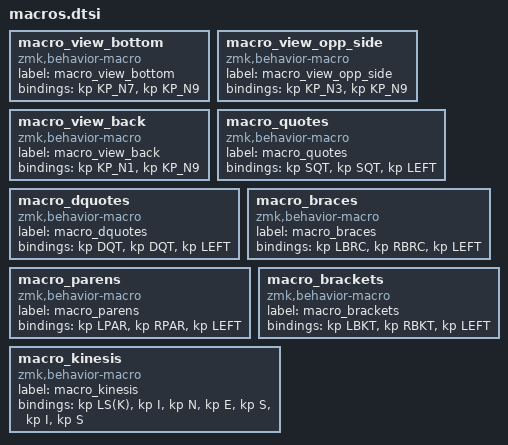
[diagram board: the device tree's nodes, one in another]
macro_view_bottom: macro_view_bottom{
compatible = "zmk,behavior-macro";
label = "macro_view_bottom";
#binding-cells = <0>;
bindings = <&kp KP_N7>, <&kp KP_N9>;
};
macro_view_opp_side: macro_view_opp_side{
compatible = "zmk,behavior-macro";
label = "macro_view_opp_side";
#binding-cells = <0>;
bindings = <&kp KP_N3>, <&kp KP_N9>;
};
macro_view_back: macro_view_back{
compatible = "zmk,behavior-macro";
label = "macro_view_back";
#binding-cells = <0>;
bindings = <&kp KP_N1>, <&kp KP_N9>;
};
macro_quotes: macro_quotes{
compatible = "zmk,behavior-macro";
label = "macro_quotes";
#binding-cells = <0>;
bindings = <&kp SQT>, <&kp SQT>, <&kp LEFT>;
};
macro_dquotes: macro_dquotes{
compatible = "zmk,behavior-macro";
label = "macro_dquotes";
#binding-cells = <0>;
bindings = <&kp DQT>, <&kp DQT>, <&kp LEFT>;
};
macro_braces: macro_braces{
compatible = "zmk,behavior-macro";
label = "macro_braces";
#binding-cells = <0>;
bindings = <&kp LBRC>, <&kp RBRC>, <&kp LEFT>;
};
macro_parens: macro_parens{
compatible = "zmk,behavior-macro";
label = "macro_parens";
#binding-cells = <0>;
bindings = <&kp LPAR>, <&kp RPAR>, <&kp LEFT>;
};
macro_brackets: macro_brackets{
compatible = "zmk,behavior-macro";
label = "macro_brackets";
#binding-cells = <0>;
bindings = <&kp LBKT>, <&kp RBKT>, <&kp LEFT>;
};
macro_kinesis: macro_kinesis{
compatible = "zmk,behavior-macro";
label = "macro_kinesis";
#binding-cells = <0>;
bindings = <&kp LS(K)>, <&kp I>, <&kp N>, <&kp E>, <&kp S>, <&kp I>, <&kp S>;
};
